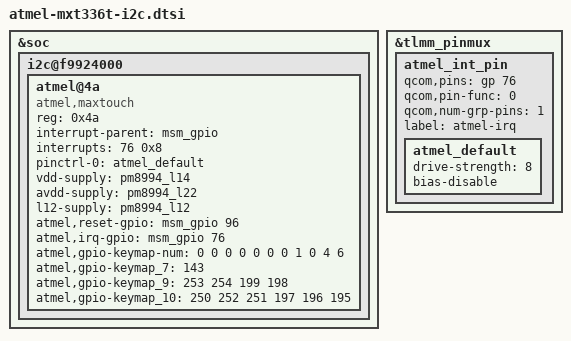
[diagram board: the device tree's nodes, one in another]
/*
 * ATMEL Key map:
 *   0: T15_T97_KEY
 *   1: T19_KEY
 *   2: T24_KEY
 *   3: T42_KEY
 *   4: T61_KEY
 *   5: T81_KEY
 *   6: T92_KEY
 *   7: T93_KEY
 *   8: T99_KEY
 *   9: T115_KEY
 *   10: T116_KEY
 */

&soc {
	i2c@f9924000 {
		status = "ok";
		#address-cells = <1>;
		#size-cells = <0>;
		atmel@4a {
			compatible = "atmel,maxtouch";
			reg = <0x4a>;
			interrupt-parent = <&msm_gpio>;
			interrupts = <76 0x8>;
			pinctrl-names = "default";
			pinctrl-0 = <&atmel_default>;
			vdd-supply = <&pm8994_l14>;
			avdd-supply = <&pm8994_l22>;
			/* L12/L14 workaround */
			l12-supply = <&pm8994_l12>;
			atmel,reset-gpio = <&msm_gpio 96 0x0>;
			atmel,irq-gpio = <&msm_gpio 76 0x8>;
			/* Numbers of each keymap keys (keymap_0 ~ keymap_10) */
			atmel,gpio-keymap-num = <0 0 0 0 0 0 0 1 0 4 6>;
			/* T93_KEY map to KEY_WAKEUP */
			atmel,gpio-keymap_7 = <143>;
			/* T115_KEY */
			atmel,gpio-keymap_9 = <253 254 199 198>;
			/* T116_KEY */
			atmel,gpio-keymap_10 = <250 252 251 197 196 195>;
		};
	};
};

&tlmm_pinmux {
	atmel_int_pin {
		qcom,pins = <&gp 76>;
		qcom,pin-func = <0>;
		qcom,num-grp-pins = <1>;
		label = "atmel-irq";
		atmel_default: atmel_default {
			drive-strength = <8>;
			bias-disable;
		};
	};
};
